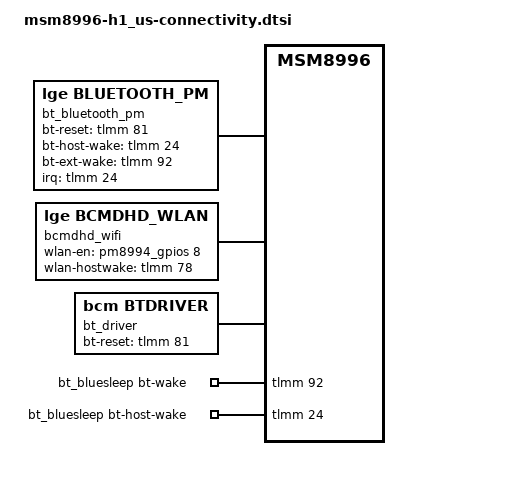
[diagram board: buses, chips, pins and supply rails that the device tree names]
/* Copyright (c) 2015, The Linux Foundation. All rights reserved.
 *
 * This program is free software; you can redistribute it and/or modify
 * it under the terms of the GNU General Public License version 2 and
 * only version 2 as published by the Free Software Foundation.
 *
 * This program is distributed in the hope that it will be useful,
 * but WITHOUT ANY WARRANTY; without even the implied warranty of
 * MERCHANTABILITY or FITNESS FOR A PARTICULAR PURPOSE.  See the
 * GNU General Public License for more details.
 */

/*[H1_BT_BRINGUP_S]*/
&blsp1_uart2 {
                /delete-property/ interupt-names;
                /delete-property/ interupts;
                /delete-property/ interupt-map;
                interrupt-names = "core_irq", "bam_irq";
                interrupts = <0 1>;
                interrupt-map = <0 &intc 0 0 108 0
                                 1 &intc 0 0 238 0>;
                /delete-property/ qcom,inject-rx-on-wakeup;
                /delete-property/ qcom,rx-char-to-inject;
                qcom,msm-obs;
};
/*[H1_BT_BRINGUP_E]*/

/ {
        /*[H1_BT_BRINGUP_S]*/
	bt_bluetooth_pm {
		compatible = "lge,bluetooth_pm";
		gpio-bt-reset = <&tlmm 81 0>;
		gpio-bt-host-wake = <&tlmm 24 0>;
		gpio-bt-ext-wake = <&tlmm 92 0>;
		interrupt-parent = <&tlmm>;
		interrupts = <24 0>;
		interrupt-names = "host_wake_interrupt";

		pinctrl-names = "bt_default";
		pinctrl-0 = <&bt_default>;
     };
        /*[H1_BT_BRINGUP_E]*/

	/* BCMDHD for Wi-Fi */
	bcmdhd_wifi {
		compatible = "lge,bcmdhd_wlan";
		wlan-en-gpio = <&pm8994_gpios 8 0>;
		wlan-hostwake-gpio = <&tlmm 78 0>;
	};

    bt_driver {
		compatible = "bcm,btdriver";
        bcm,bt-reset-gpio = <&tlmm 81 0>;
		status = "ok";
	};

	bt_bluesleep {
		compatible = "bcm,bluesleep";
		/*
		pinctrl-names = "bt_wake_default","bt_wake_active","bt_wake_suspend",
						"host_wake_default","host_wake_active","host_wake_suspend";
		pinctrl-0 = <&bt_wake_default_s>;
		pinctrl-1 = <&bt_wake_active_s>;
		pinctrl-2 = <&bt_wake_suspend_s>;
		pinctrl-3 = <&host_wake_default_s>;
		pinctrl-4 = <&host_wake_active_s>;
		pinctrl-5 = <&host_wake_suspend_s>;
		*/
		bcm,bt-wake-gpio = <&tlmm 92 0>;
		bcm,bt-host-wake-gpio = <&tlmm 24 0>;
		status = "ok";
	};
};
